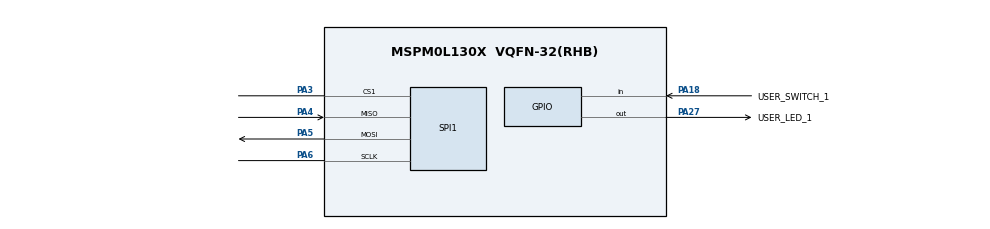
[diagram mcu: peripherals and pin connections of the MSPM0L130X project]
// @cliArgs --device "MSPM0L130X" --package "VQFN-32(RHB)" --part "Default"
// @cliArgs --board /ti/boards/LP_MSPM0L1306 --rtos nortos

/**
 * Import the modules used in this configuration.
 */
const GPIO  = scripting.addModule("/ti/driverlib/GPIO", {}, false);
const GPIO1 = GPIO.addInstance();
const GPIO2 = GPIO.addInstance();
const SPI   = scripting.addModule("/ti/driverlib/SPI", {}, false);
const SPI1  = SPI.addInstance();

/**
 * Write custom configuration values to the imported modules.
 */
GPIO1.$name                         = "GPIO_LEDS";
GPIO1.associatedPins[0].$name       = "USER_LED_1";
GPIO1.associatedPins[0].pin.$assign = "PA27";

const Board = scripting.addModule("/ti/driverlib/Board", {}, false);

GPIO2.$name                         = "GPIO_SWITCHES";
GPIO2.associatedPins[0].$name       = "USER_SWITCH_1";
GPIO2.associatedPins[0].direction   = "INPUT";
GPIO2.associatedPins[0].interruptEn = true;
GPIO2.associatedPins[0].polarity    = "RISE";
GPIO2.associatedPins[0].pin.$assign = "PA18";

SPI1.$name                      = "SPI_0";
SPI1.targetBitRate              = 500000;
SPI1.txFifoThreshold            = "DL_SPI_TX_FIFO_LEVEL_ONE_FRAME";
SPI1.enabledInterrupts          = ["RX"];
SPI1.chipSelect                 = ["1"];
SPI1.rxFifoThreshold            = "DL_SPI_RX_FIFO_LEVEL_ONE_FRAME";
SPI1.peripheral.$assign         = "SPI0";
SPI1.peripheral.sclkPin.$assign = "PA6";
SPI1.peripheral.mosiPin.$assign = "PA5";
SPI1.peripheral.misoPin.$assign = "PA4";
SPI1.peripheral.cs1Pin.$assign  = "PA3";

const SYSCTL              = scripting.addModule("/ti/driverlib/SYSCTL", {}, false);
SYSCTL.peripheral.$assign = "SYSCTL";
SYSCTL.clockTreeEn = true;
